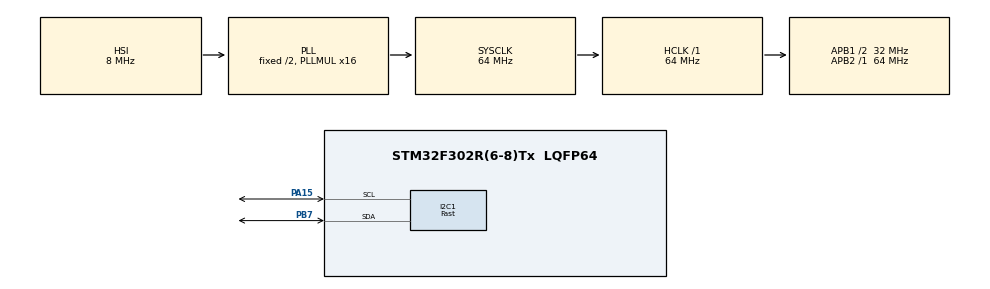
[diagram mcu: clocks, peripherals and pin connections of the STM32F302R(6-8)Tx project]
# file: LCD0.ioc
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I2C1.I2C_Speed_Mode=I2C_Fast
I2C1.Timing=0x0010020A
Mcu.Family=STM32F3
Mcu.Name=STM32F302R(6-8)Tx
Mcu.Package=LQFP64
NVIC.PriorityGroup=NVIC_PRIORITYGROUP_0
PA13.Mode=Serial_Wire
PA13.Signal=SYS_JTMS-SWDIO
PA14.Mode=Serial_Wire
PA14.Signal=SYS_JTCK-SWCLK
PA15.Mode=I2C
PA15.Signal=I2C1_SCL
PB7.Mode=I2C
PB7.Signal=I2C1_SDA
ProjectManager.HeapSize=0x200
ProjectManager.StackSize=0x400
ProjectManager.TargetToolchain=STM32CubeIDE
RCC.AHBFreq_Value=64000000
RCC.APB1CLKDivider=RCC_HCLK_DIV2
RCC.APB1Freq_Value=32000000
RCC.APB1TimFreq_Value=64000000
RCC.APB2Freq_Value=64000000
RCC.APB2TimFreq_Value=64000000
RCC.CortexFreq_Value=64000000
RCC.HCLKFreq_Value=64000000
RCC.HSE_VALUE=8000000
RCC.HSI_VALUE=8000000
RCC.PLLM=8
RCC.PLLMUL=RCC_PLL_MUL16
RCC.PLLN=336
RCC.PLLP=RCC_PLLP_DIV4
RCC.PLLQ=7
RCC.RCC_PLLsource_Clock_Source_FROM_HSE=RCC_HSE_PREDIV_DIV2
RCC.SYSCLKFreq_VALUE=64000000
RCC.SYSCLKSourceVirtual=RCC_SYSCLKSOURCE_PLLCLK
RCC.USBFreq_Value=64000000
board=NUCLEO-F302R8

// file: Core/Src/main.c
/* USER CODE BEGIN Header */
/**
  ******************************************************************************
  * @file           : main.c
  * @brief          : Main program body
  ******************************************************************************
  * @attention
  *
  * Copyright (c) 2025 STMicroelectronics.
  * All rights reserved.
  *
  * This software is licensed under terms that can be found in the LICENSE file
  * in the root directory of this software component.
  * If no LICENSE file comes with this software, it is provided AS-IS.
  *
  ******************************************************************************
  */
/* USER CODE END Header */
#include "main.h"

/* USER CODE BEGIN Includes */
#include "fonts.h"
#include "ssd1306.h"
/* USER CODE END Includes */

I2C_HandleTypeDef hi2c1;

void SystemClock_Config(void);
static void MX_GPIO_Init(void);
static void MX_I2C1_Init(void);

int main(void)
{

  /* MCU Configuration--------------------------------------------------------*/

  /* Reset of all peripherals, Initializes the Flash interface and the Systick. */
  HAL_Init();

  /* Configure the system clock */
  SystemClock_Config();

  /* Initialize all configured peripherals */
  MX_GPIO_Init();
  MX_I2C1_Init();
  /* USER CODE BEGIN 2 */
  SSD1306_Init();

  SSD1306_GotoXY (5,0);
  SSD1306_Puts ("Hello", &Font_11x18, 1);
  SSD1306_GotoXY (5, 45);
  SSD1306_Puts ("World!", &Font_11x18, 1);
  SSD1306_UpdateScreen();
  HAL_Delay (1000);

  /* USER CODE END 2 */
  /* USER CODE BEGIN WHILE */
  while (1)
  {
	  //Thanks to Nizar Mohideen YouTube Channel
	  //This is a simple project. Using HAL_Delay() might be not a good idea for professional projects.
	  SSD1306_ScrollRight(0,7);
	  HAL_Delay(2000);
	  SSD1306_ScrollLeft(0,7);
	  HAL_Delay(2000);
    /* USER CODE END WHILE */

  }
}

void SystemClock_Config(void)
{
  RCC_OscInitTypeDef RCC_OscInitStruct = {0};
  RCC_ClkInitTypeDef RCC_ClkInitStruct = {0};
  RCC_PeriphCLKInitTypeDef PeriphClkInit = {0};

  /** Initializes the RCC Oscillators according to the specified parameters
  * in the RCC_OscInitTypeDef structure.
  */
  RCC_OscInitStruct.OscillatorType = RCC_OSCILLATORTYPE_HSI;
  RCC_OscInitStruct.HSIState = RCC_HSI_ON;
  RCC_OscInitStruct.HSICalibrationValue = RCC_HSICALIBRATION_DEFAULT;
  RCC_OscInitStruct.PLL.PLLState = RCC_PLL_ON;
  RCC_OscInitStruct.PLL.PLLSource = RCC_PLLSOURCE_HSI;
  RCC_OscInitStruct.PLL.PLLMUL = RCC_PLL_MUL16;
  if (HAL_RCC_OscConfig(&RCC_OscInitStruct) != HAL_OK)
  {
    Error_Handler();
  }

  /** Initializes the CPU, AHB and APB buses clocks
  */
  RCC_ClkInitStruct.ClockType = RCC_CLOCKTYPE_HCLK|RCC_CLOCKTYPE_SYSCLK
                              |RCC_CLOCKTYPE_PCLK1|RCC_CLOCKTYPE_PCLK2;
  RCC_ClkInitStruct.SYSCLKSource = RCC_SYSCLKSOURCE_PLLCLK;
  RCC_ClkInitStruct.AHBCLKDivider = RCC_SYSCLK_DIV1;
  RCC_ClkInitStruct.APB1CLKDivider = RCC_HCLK_DIV2;
  RCC_ClkInitStruct.APB2CLKDivider = RCC_HCLK_DIV1;

  if (HAL_RCC_ClockConfig(&RCC_ClkInitStruct, FLASH_LATENCY_2) != HAL_OK)
  {
    Error_Handler();
  }
  PeriphClkInit.PeriphClockSelection = RCC_PERIPHCLK_I2C1;
  PeriphClkInit.I2c1ClockSelection = RCC_I2C1CLKSOURCE_HSI;
  if (HAL_RCCEx_PeriphCLKConfig(&PeriphClkInit) != HAL_OK)
  {
    Error_Handler();
  }
}

static void MX_I2C1_Init(void)
{

  hi2c1.Instance = I2C1;
  hi2c1.Init.Timing = 0x0010020A;
  hi2c1.Init.OwnAddress1 = 0;
  hi2c1.Init.AddressingMode = I2C_ADDRESSINGMODE_7BIT;
  hi2c1.Init.DualAddressMode = I2C_DUALADDRESS_DISABLE;
  hi2c1.Init.OwnAddress2 = 0;
  hi2c1.Init.OwnAddress2Masks = I2C_OA2_NOMASK;
  hi2c1.Init.GeneralCallMode = I2C_GENERALCALL_DISABLE;
  hi2c1.Init.NoStretchMode = I2C_NOSTRETCH_DISABLE;
  if (HAL_I2C_Init(&hi2c1) != HAL_OK)
  {
    Error_Handler();
  }

  /** Configure Analogue filter
  */
  if (HAL_I2CEx_ConfigAnalogFilter(&hi2c1, I2C_ANALOGFILTER_ENABLE) != HAL_OK)
  {
    Error_Handler();
  }

  /** Configure Digital filter
  */
  if (HAL_I2CEx_ConfigDigitalFilter(&hi2c1, 0) != HAL_OK)
  {
    Error_Handler();
  }

}

static void MX_GPIO_Init(void)
{

  /* GPIO Ports Clock Enable */
  __HAL_RCC_GPIOA_CLK_ENABLE();
  __HAL_RCC_GPIOB_CLK_ENABLE();

}

void Error_Handler(void)
{
  __disable_irq();
  while (1)
  {
  }
}
